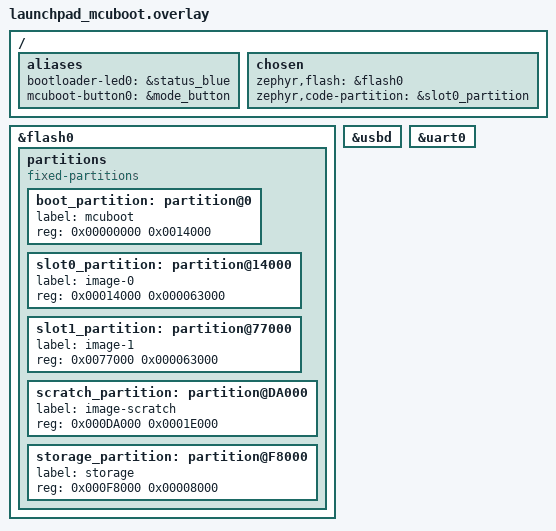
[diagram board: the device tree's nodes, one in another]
/ {
	aliases {
		bootloader-led0 = &status_blue;
		mcuboot-button0 = &mode_button;
	};

	chosen {
		zephyr,flash = &flash0;
		zephyr,code-partition = &slot0_partition;
	};
};

// Defined in https://github.com/zephyrproject-rtos/zephyr/blob/main/boards/arm/particle_xenon/dts/mesh_feather.dtsi
/delete-node/ &boot_partition;
/delete-node/ &slot0_partition;
/delete-node/ &slot1_partition;
/delete-node/ &scratch_partition;
/delete-node/ &storage_partition;

&flash0 {
	partitions {
		compatible = "fixed-partitions";
		#address-cells = <1>;
		#size-cells = <1>;

		/* MCUboot placed after Nordic MBR.
		 * The size of this partition ensures that MCUBoot
		 * can be built with CDC ACM support and w/o optimizations.
		 */
		boot_partition: partition@0 {
			label = "mcuboot";
			reg = <0x00000000 0x0014000>;
		};

		slot0_partition: partition@14000 {
			label = "image-0";
			reg = <0x00014000 0x000063000>;
		};
		slot1_partition: partition@77000 {
			label = "image-1";
			reg = <0x0077000 0x000063000>;
		};
		scratch_partition: partition@DA000 {
			label = "image-scratch";
			reg = <0x000DA000 0x0001E000>;
		};

		/*
		 * The flash starting at 0x000f8000 and ending at
		 * 0x000fffff is reserved for use by the application.
		 */

		/*
		 * Storage partition will be used by FCB/LittleFS/NVS
		 * if enabled.
		 */
		storage_partition: partition@F8000 {
			label = "storage";
			reg = <0x000F8000 0x00008000>;
		};
	};
};

&usbd {
	status = "okay";
};

&uart0 {
	status = "okay";
};
